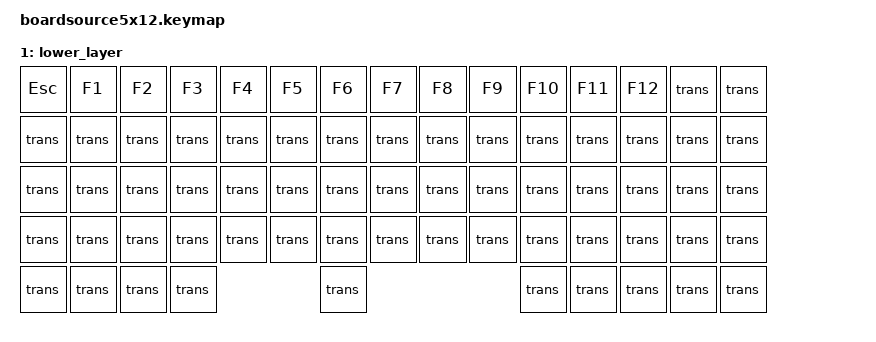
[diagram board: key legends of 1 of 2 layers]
/*
 * Copyright (c) 2021 The ZMK Contributors
 *
 * SPDX-License-Identifier: MIT
 */

#include <behaviors.dtsi>
#include <dt-bindings/zmk/keys.h>
#include <dt-bindings/zmk/bt.h>
#include <dt-bindings/zmk/outputs.h>


/ {
    keymap {
        compatible = "zmk,keymap";

        default_layer {
            // ------------------------------------------------------------------------------------------
            // |  ESC  |  1   |  2   |  3   |  4   |  5   |   6   |  7    |  8   |  9   |   0   |   ß   |   ´   |  BSPC  |  INS  |
            // |  TAB  |  Q   |  W   |  E   |  R   |  T   |   Z   |  U    |  I   |  O   |   P   |   Ü   |   +   |   |    |  DEL  |
            // | CAPSL |  A   |  S   |  D   |  F   |  G   |   H   |  J    |  K   |  L   |   Ö   |   Ä   |       |  ENT   |  PGUP |
            // | Shift |  Y   |  X   |  C   |  V   |  B   |   N   |  M    |  ,   |  .   |   -   |       | Shift |  UP    |  PGDN |
            // | CTRL  | WIN  | LALT |      |      | SPACE|       |       |      | RALT |   FN  | CTRL  |  LEFT |  DWN   |  RGHT |


            bindings = <
                &kp ESC   &kp N1   &kp N2   &kp N3   &kp N4     &kp N5      &kp N6      &kp N7  &kp N8      &kp N9      &kp N0          &kp ß     &KC_MINS  &kp BSPC  &kp INS
                &kp TAB   &kp Q    &kp W    &kp E    &kp R      &kp T       &kp Y       &kp U   &kp I       &kp O       &kp P           &kp Ü     &kp PLUS  &kp BKSLH &kp DEL
                &kp CAPS  &kp A    &kp S    &kp D    &kp F      &kp G       &kp H       &kp J   &kp K       &kp L       &kp Ö           &kp Ä               &kp ENT   &kp PG_UP
                &kp LSHFT &kp Y    &kp X    &kp C    &kp V      &kp B       &kp N       &kp M   &kp COMMA   &kp DOT     &kp MINUS                 &kp RSHFT &kp UP    &kp PG_DN
                &kp LCTRL &kp LGUI &kp LALT &kp LGUI            &kp SPACE                                   &kp RALT    &mo lower_layer &kp RCTRL &kp LEFT  &kp DOWN  &kp RIGHT
            >;
        };

        lower_layer {
            // -------------------------------------------------------------------------------------------
            // |  ESC  |  F1  |  F2  |  F3  |  F4  |  F5  |   F6  |  F7   |  F8  |  F9  |  F10  |  F11  |  F12  |        |       |
            // |       |      |      |      |      |      |       |       |      |      |       |       |       |        |       |
            // |       |      |      |      |      |      |       |       |      |      |       |       |       |        |       |
            // |       |      |      |      |      |      |       |       |      |      |       |       |       |        |       |
            // |       |      |      |      |      |      |       |       |      |      |       |       |       |        |       |
            bindings = <
                &kp ESC   &kp F1    &kp F2    &kp F3    &kp F4    &kp F5    &kp F6    &kp F7    &kp F8    &kp F9    &kp F10   &kp F11   &kp F12   &kp trans &kp trans
                &kp trans &kp trans &kp trans &kp trans &kp trans &kp trans &kp trans &kp trans &kp trans &kp trans &kp trans &kp trans &kp trans &kp trans &kp trans
                &kp trans &kp trans &kp trans &kp trans &kp trans &kp trans &kp trans &kp trans &kp trans &kp trans &kp trans &kp trans &kp trans &kp trans &kp trans
                &kp trans &kp trans &kp trans &kp trans &kp trans &kp trans &kp trans &kp trans &kp trans &kp trans &kp trans &kp trans &kp trans &kp trans &kp trans
                &kp trans &kp trans &kp trans &kp trans                     &kp trans                               &kp trans &kp trans &kp trans &kp trans &kp trans
            >;
        };
    };
};
